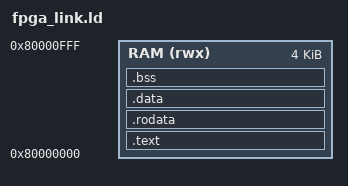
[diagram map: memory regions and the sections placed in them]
/* Linker script for FPGA bare-metal firmware */
/* RAM: 4KB at 0x80000000 */

ENTRY(_start)

MEMORY
{
    RAM (rwx) : ORIGIN = 0x80000000, LENGTH = 4K
}

SECTIONS
{
    .text : {
        *(.text)
        *(.text.*)
    } > RAM

    .rodata : {
        *(.rodata)
        *(.rodata.*)
    } > RAM

    .data : {
        *(.data)
        *(.data.*)
    } > RAM

    .bss : {
        __bss_start = .;
        *(.bss)
        *(.bss.*)
        *(COMMON)
        __bss_end = .;
    } > RAM

    /* Stack at top of RAM */
    _stack_top = ORIGIN(RAM) + LENGTH(RAM);
}
